# ESP32S31_RADIO register map
Vendor: Espressif; Series: ESP32-S31; File version: 3.52
Registers are 32-bit, read-write, no defined reset value unless marked. A register's access mark holds for its fields unless they carry their own. Offsets are from the block's base; [hi:lo] are bit positions; {n}, {i} and the like mark numbered series.

## WIFI_MAC_HE_BUFFER_STATUS — Eight interleaved hardware/software Buffer Status Report values and their shared control. Complete dbg_read_bsr_info names every exposed field. Complete hal_he_get_hw_txq_bsr independently proves the eight-byte stride and low twenty-bit hardware value. The independent blob and ROM libpp[hal_mac_tx.o]::mac_tx_set_tb and rom[]::mac_tx_set_tb bodies prove the write-side scheduler interpretation: for logical queues zero through three they replace the corresponding software BSR low twenty bits with the sum of every linked frame-state halfword at offset 0x22, then OR the queue bit into CONTROL[7:0]. Complete dbg_read_tx_ppdu independently names that exact halfword msdu_len, proving that this is an original-MSDU byte sum rather than MPDU, PSDU or encoded A-MPDU length. Complete HE BlockAck response/deletion paths separately select and clear TID_BITMAP bits through hal_he_set_tid_bitmap and hal_he_clr_tid_bitmap. Open HE HIL observed TID_BITMAP=1 immediately after the successful TID0 AddBA transition while sustained DCM A-MPDU remained clean. A later rev0 HIL reproduced the complete ROM write order with a 47104-byte TID0 queue: CONTROL validity read back one while SOFTWARE_BSR already read zero. This qualifies the write-side address and validity edge but leaves the zero as a live-update/read-latch ambiguity until a real AP Trigger is observed.
Base 0x20104D74
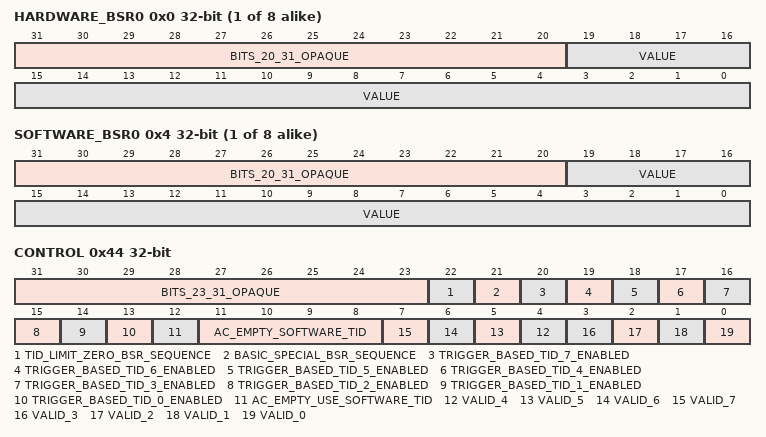
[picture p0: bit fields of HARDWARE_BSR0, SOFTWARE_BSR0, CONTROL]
{0x0+8i} HARDWARE_BSR{i} (i=0..7) ro — Project-assigned name. WDEVTXQBSR_HW[0-7].
  [31:20] BITS_20_31_OPAQUE — Opaque: meaning not established.
  [19:0] VALUE — Project-assigned name.
{0x4+8i} SOFTWARE_BSR{i} (i=0..7) — Project-assigned name. WDEVTXQBSR_SW[0-7]. The debug decoder reads all eight low-twenty-bit values. Complete blob and ROM libpp[hal_mac_tx.o]::mac_tx_set_tb and rom[]::mac_tx_set_tb independently prove write semantics for logical queues zero through three: preserve bits 31:20 and replace VALUE with the sum of linked frame-state +0x22 halfwords before publishing the queue-ready bit. Complete dbg_read_tx_ppdu names that halfword msdu_len. Rev0 open HIL programmed 47104 for logical queue two with the exact ROM sequence, then observed VALUE zero immediately after validity became visible. Treat reads as live hardware state rather than durable software-write readback until a Trigger HIL resolves whether the value was consumed or rejected.
  [31:20] BITS_20_31_OPAQUE — Opaque: meaning not established.
  [19:0] VALUE — Project-assigned name. Software BSR value. On the recovered Trigger-based TX path this is the low-twenty-bit sum of the original MSDU lengths from linked frame-state +0x22, not the encoded MPDU/PSDU lengths.
0x44 CONTROL — Project-assigned name. WDEVTXQBSR_CTRL. Complete dbg_read_bsr_info decodes all fields below. Complete blob and ROM libpp[hal_mac_tx.o]::mac_tx_set_tb and rom[]::mac_tx_set_tb perform a fresh-read RMW that ORs 1<<logical_queue into bits 7:0 after the queue configuration and software BSR value are visible; the debug function names these bits WDEVTXQBSR_VD[0-7], so the neutral validity name is retained. Complete hal_he_set_tid_bitmap and hal_he_clr_tid_bitmap independently update TID_BITMAP through two fresh reads followed by one write. Open HE HIL qualified the TID0 set edge after successful AddBA and later read back logical queue two validity immediately after the exact ROM publication sequence.
  [31:23] BITS_23_31_OPAQUE — Opaque: meaning not established.
  [22] TID_LIMIT_ZERO_BSR_SEQUENCE — Project-assigned name.
  [21] BASIC_SPECIAL_BSR_SEQUENCE — Project-assigned name.
  [20] TRIGGER_BASED_TID_7_ENABLED — Project-assigned name. Trigger-based TID seven enabled by successful HE BlockAck setup.
  [19] TRIGGER_BASED_TID_6_ENABLED — Project-assigned name. Trigger-based TID six enabled by successful HE BlockAck setup.
  [18] TRIGGER_BASED_TID_5_ENABLED — Project-assigned name. Trigger-based TID five enabled by successful HE BlockAck setup.
  [17] TRIGGER_BASED_TID_4_ENABLED — Project-assigned name. Trigger-based TID four enabled by successful HE BlockAck setup.
  [16] TRIGGER_BASED_TID_3_ENABLED — Project-assigned name. Trigger-based TID three enabled by successful HE BlockAck setup.
  [15] TRIGGER_BASED_TID_2_ENABLED — Project-assigned name. Trigger-based TID two enabled by successful HE BlockAck setup.
  [14] TRIGGER_BASED_TID_1_ENABLED — Project-assigned name. Trigger-based TID one enabled by successful HE BlockAck setup.
  [13] TRIGGER_BASED_TID_0_ENABLED — Project-assigned name. Trigger-based TID zero enabled by successful HE BlockAck setup.
  [12] AC_EMPTY_USE_SOFTWARE_TID — Project-assigned name.
  [11:8] AC_EMPTY_SOFTWARE_TID — Project-assigned name. TID used when AC_EMPTY_USE_SW_TID is set.
  [n] VALID_{n} (n=4..7) — Project-assigned name. WDEVTXQBSR_VD[{n}]. No write-side queue interpretation is currently claimed.
  [3] VALID_3 — Project-assigned name. WDEVTXQBSR_VD[3]. Complete libpp[hal_mac_tx.o]::mac_tx_set_tb/rom[]::mac_tx_set_tb also proves this is the write-side Trigger-ready bit for logical queue three.
  [2] VALID_2 — Project-assigned name. WDEVTXQBSR_VD[2]. Complete libpp[hal_mac_tx.o]::mac_tx_set_tb/rom[]::mac_tx_set_tb also proves this is the write-side Trigger-ready bit for logical queue two.
  [1] VALID_1 — Project-assigned name. WDEVTXQBSR_VD[1]. Complete libpp[hal_mac_tx.o]::mac_tx_set_tb/rom[]::mac_tx_set_tb also proves this is the write-side Trigger-ready bit for logical queue one.
  [0] VALID_0 — Project-assigned name. WDEVTXQBSR_VD[0]. Complete libpp[hal_mac_tx.o]::mac_tx_set_tb/rom[]::mac_tx_set_tb also proves this is the write-side Trigger-ready bit for logical queue zero.
